# EFR32BG21B020F1024IM32 register map
Vendor: Silicon Labs; Series: EFR32; File version: B
Registers are 32-bit, read-write, reset 0x0 unless marked. A register's access mark holds for its fields unless they carry their own. Offsets are from the block's base; [hi:lo] are bit positions; {n}, {i} and the like mark numbered series; 'fields as' and 'values as' point back to an identical list.

## AMUXCP0_S — AMUXCP0_S Registers
Base 0x4A020000
Same registers: AMUXCP0_NS 0x5A020000
0x00 IPVERSION ro
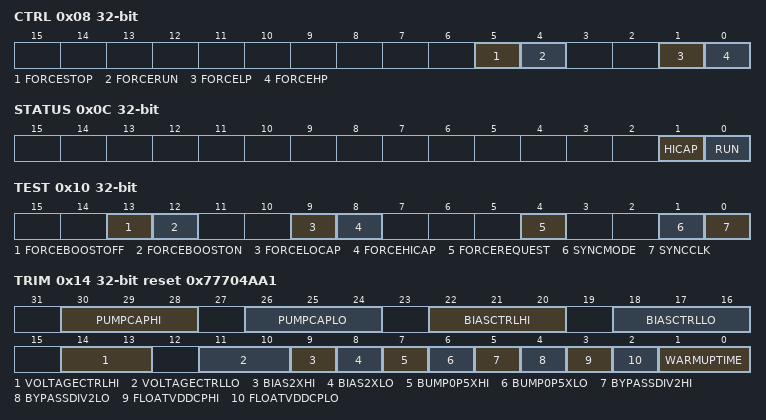
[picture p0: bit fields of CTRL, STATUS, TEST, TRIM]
0x08 CTRL — Control
  [5] FORCESTOP
  [4] FORCERUN
  [1] FORCELP — Force Low Power
  [0] FORCEHP — Force High Power
0x0C STATUS ro
  [1] HICAP — high cap
  [0] RUN — running
0x10 TEST
  [13] FORCEBOOSTOFF
  [12] FORCEBOOSTON
  [9] FORCELOCAP — Force low capacitance driver
  [8] FORCEHICAP — Force high capacitance driver
  [4] FORCEREQUEST
  [1] SYNCMODE
  [0] SYNCCLK — Sync Clock
0x14 TRIM reset 0x77704AA1
  [30:28] PUMPCAPHI — Pump Cap High Power
  [26:24] PUMPCAPLO — Pump Cap Low Power
  [22:20] BIASCTRLHI — Bias Control High Power
  [18:16] BIASCTRLLO — Bias Control Low Power
  [14:13] VOLTAGECTRLHI — Charge Pump Voltage Control High Power
  [11:10] VOLTAGECTRLLO — Charge Pump Voltage Control Low Power
  [9] BIAS2XHI — Bias 2x High Power
  [8] BIAS2XLO — Bias 2x Low Power
  [7] BUMP0P5XHI — Bump 0.5X High Power
  [6] BUMP0P5XLO — Bump 0.5X Low Power
  [5] BYPASSDIV2HI — Bypass Div2 High Power
  [4] BYPASSDIV2LO — Bypass Div2 Low Power
  [3] FLOATVDDCPHI — Float VDDCP High Power
  [2] FLOATVDDCPLO — Float VDDCP Low Power
  [1:0] WARMUPTIME
    0=WUCYCLES72 (Warm up cycle = 72; 3.6us @20 MHz); 1=WUCYCLES96 (Warm up cycle = 96; 4.8us @ 20 MHz); 2=WUCYCLES128 (Warm up cycle = 128; 6.4us @ 20 MHz); 3=WUCYCLES160 (Warm up cycle = 160; 8.0us @ 20 MHz)

## SEMAILBOX_S_HOST — SEMAILBOX_S_HOST Registers
Base 0x4C000000
Same registers: SEMAILBOX_NS_HOST 0x5C000000
{0x0+4i} DATA{i} (i=0..15) — RX/TX FIFO DATA
  [31:0] DATA — FIFO Data
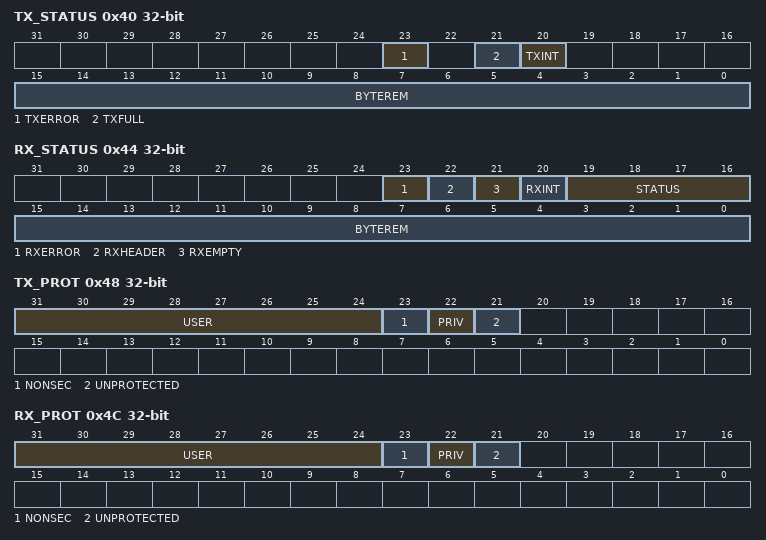
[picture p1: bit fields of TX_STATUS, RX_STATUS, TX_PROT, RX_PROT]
0x40 TX_STATUS ro
  [23] TXERROR — TX Error Flag
  [21] TXFULL — TX FIFO Full
  [20] TXINT — Interrupt Status
  [15:0] BYTEREM — Bytes Remaining
0x44 RX_STATUS ro
  [23] RXERROR — RX Error Flag
  [22] RXHEADER
  [21] RXEMPTY — RX FIFO Empty
  [20] RXINT — Interrupt Status
  [19:16] STATUS — Message Status
  [15:0] BYTEREM — Bytes Remaining
0x48 TX_PROT ro
  [31:24] USER — User Bits
  [23] NONSEC — Non-Secure Access
  [22] PRIV — Privileged Access
  [21] UNPROTECTED
0x4C RX_PROT ro
  fields as TX_PROT
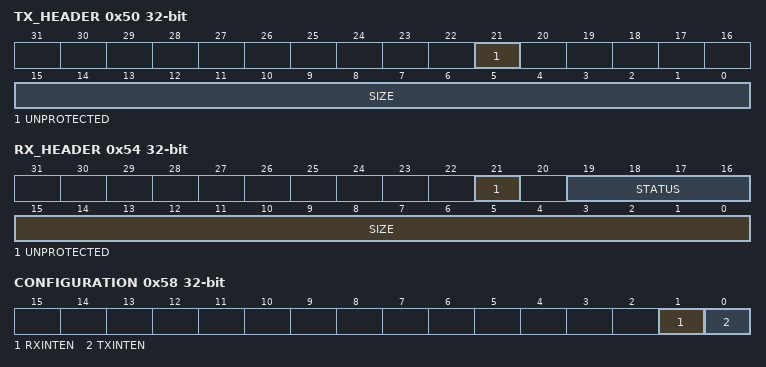
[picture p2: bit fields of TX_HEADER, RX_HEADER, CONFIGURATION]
0x50 TX_HEADER wo
  [21] UNPROTECTED
  [15:0] SIZE — Command Size
0x54 RX_HEADER ro
  [21] UNPROTECTED
  [19:16] STATUS — Command Status
  [15:0] SIZE
0x58 CONFIGURATION
  [1] RXINTEN — RX Interrupt Enable
  [0] TXINTEN — TX Interrupt Enable

## RFCRC_S — RFCRC_S Registers
Base 0xA8010000
Same registers: RFCRC_NS 0xB8010000
0x00 IPVERSION ro
0x04 EN
  [0] EN — Enable peripheral clock to this module
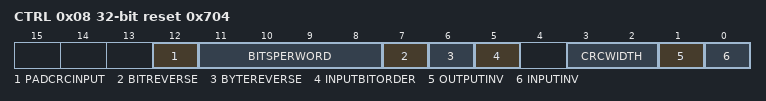
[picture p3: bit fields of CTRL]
0x08 CTRL reset 0x704
  [12] PADCRCINPUT — Pad CRC input data
    0=No zero-padding of CRC input data is applied; 1=CRC input data is zero-padded, such that the number of bytes over which the CRC value is calculated at least equals the length of the calculated CRC value
  [11:8] BITSPERWORD — Number of bits per input word
  [7] BITREVERSE — Reverse CRC bit ordering over air
    0=NORMAL (The bit ordering of CRC data is the same as defined by the BITORDER field in the Frame Controller.); 1=REVERSED (The bit ordering of CRC data is the opposite as defined by the BITORDER field in the Frame Controller.)
  [6] BYTEREVERSE — Reverse CRC byte ordering over air
    0=NORMAL (The least significant byte of the CRC register is transferred first over air via the Frame Controller.); 1=REVERSED (The most significant byte of the CRC register is transferred first over air via the Frame Controller.)
  [5] INPUTBITORDER — CRC input bit ordering setting
    0=LSBFIRST (The least significant data bit is first input to the CRC generator.); 1=MSBFIRST (The most significant data bit is first input to the CRC generator.)
  [3:2] CRCWIDTH
    0=8 bit (1 Byte) CRC code; 1=16 bit (2 Bytes) CRC code; 2=24 bit (3 Bytes) CRC code; 3=32 bit (4 Bytes) CRC code
  [1] OUTPUTINV — Output Invert
  [0] INPUTINV — Input Invert
0x0C STATUS ro
  [0] BUSY — CRC Running
0x10 CMD wo
  [0] INITIALIZE — Initialize CRC
0x14 INPUTDATA wo
  [15:0] INPUTDATA
0x18 INIT
  [31:0] INIT — CRC Initialization Value
0x1C DATA ro
  [31:0] DATA — CRC Data Register
0x20 POLY
  [31:0] POLY — CRC Polynomial Value
